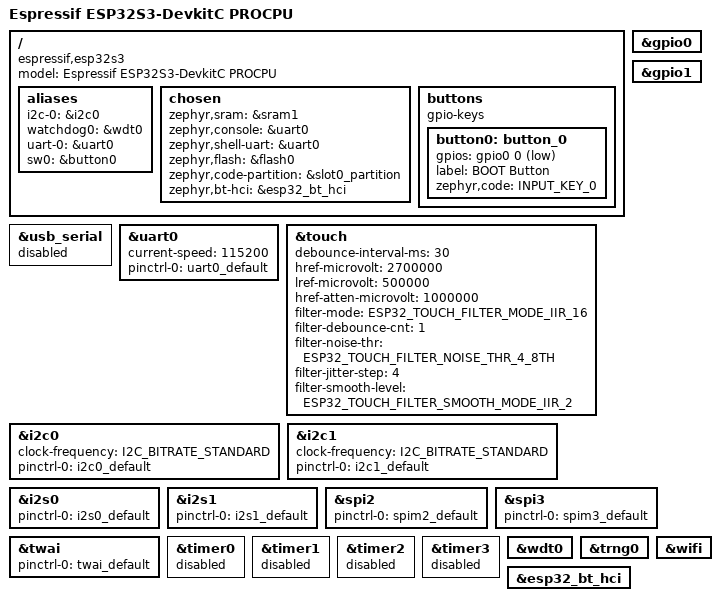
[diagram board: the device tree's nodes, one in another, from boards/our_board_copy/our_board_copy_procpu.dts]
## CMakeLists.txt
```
cmake_minimum_required(VERSION 3.20.0)

list(APPEND BOARD_ROOT ${CMAKE_CURRENT_SOURCE_DIR}/../)
find_package(Zephyr REQUIRED)
project(my_zephyr_app)

target_sources(app PRIVATE src/main.cpp)
add_subdirectory(drivers/our_driver)
```

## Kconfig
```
menuconfig LED_SUBSYSTEM
    bool "LED Subsystem"
    default n

if LED_SUBSYSTEM
    config APP_HEARTBEAT_PERIOD_MS
    	int "App Heartbeat period (100-2000)ms"
    	default 500
    	range 100 2000

    choice
        prompt "LED blink sleep time"
        default BLINK_SLEEP_1000MS

    config BLINK_SLEEP_250MS
        bool "250ms (very fast)"

    config BLINK_SLEEP_500MS
        bool "500ms (fast)"

    config BLINK_SLEEP_1000MS
        bool "1s (medium)"

    config BLINK_SLEEP_2000MS
        bool "2s (slow)"
    endchoice

    config BLINK_SLEEP_TIME_MS
        int
        depends on BLINK_SLEEP_250MS || BLINK_SLEEP_500MS || BLINK_SLEEP_1000MS || BLINK_SLEEP_2000MS
        default 250  if BLINK_SLEEP_250MS
        default 500  if BLINK_SLEEP_500MS
        default 1000 if BLINK_SLEEP_1000MS
        default 2000 if BLINK_SLEEP_2000MS
        default 0

    menuconfig ADVANCED_LED_SETTINGS
        bool "Advanced LED settings"
        default n

    if ADVANCED_LED_SETTINGS

        config LED_BRIGHTNESS
            int "LED brightness (0-100)"
            default 100
            range 0 100
            help
                Set the LED brightness level (0-100%)

        config LED_FADE_DURATION_MS
            int "LED fade duration (ms)"
            default 500
            range 0 5000
            help
                Set the duration for LED fade in/out effects in milliseconds

        menu "Expert settings"
            visible if ADVANCED_LED_SETTINGS
            config ENABLE_LED_DEBUGGING
                bool "Enable LED debugging"
                default n
                help
                    Enable debug output for LED operations (not recommended for production)

            config CUSTOM_LED_PATTERN
                bool "Custom blink pattern"
                default n
                help
                    Define a custom LED blinking pattern.
        endmenu #Expert settings

    endif #ADVANCED_LED_SETTINGS
endif #LED_SUBSYSTEM

source "Kconfig.zephyr"
rsource "drivers/our_driver/Kconfig"
```

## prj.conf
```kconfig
CONFIG_GPIO=y
CONFIG_LOG=y
CONFIG_LED_SUBSYSTEM=y
CONFIG_BLINK_SLEEP_1000MS=y
CONFIG_APP_HEARTBEAT_PERIOD_MS=1000
CONFIG_SHELL=y
CONFIG_SHELL_CMDS=y
CONFIG_SHELL_TAB=y
CONFIG_SHELL_TAB_AUTOCOMPLETION=y
CONFIG_SHELL_HISTORY=y
CONFIG_SHELL_LOG_BACKEND=y
```

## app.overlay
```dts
/{
    aliases {
        app-led = &led0;
    };

    leds {
        compatible = "gpio-leds";
        led0: led_0 {
            gpios = <&gpio0 48 GPIO_ACTIVE_HIGH>; //GPIO 48
            label = "LED 0";
        };
    };

    our_driver0: our_driver {
        compatible = "our,driver";
        status = "okay";
    };

};
```

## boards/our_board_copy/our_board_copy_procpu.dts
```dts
/*
 * Copyright (c) 2024-2025 Espressif Systems (Shanghai) Co., Ltd.
 *
 * SPDX-License-Identifier: Apache-2.0
 */
/dts-v1/;

#include <espressif/esp32s3/esp32s3_wroom_n8.dtsi>
#include <zephyr/dt-bindings/input/input-event-codes.h>
#include <zephyr/dt-bindings/input/esp32-touch-sensor-input.h>
#include <espressif/partitions_0x0_amp.dtsi>
#include "our_board_copy-pinctrl.dtsi"

/ {
	model = "Espressif ESP32S3-DevkitC PROCPU";
	compatible = "espressif,esp32s3";

	aliases {
		i2c-0 = &i2c0;
		watchdog0 = &wdt0;
		uart-0 = &uart0;
		sw0 = &button0;
	};

	chosen {
		zephyr,sram = &sram1;
		zephyr,console = &uart0;
		zephyr,shell-uart = &uart0;
		zephyr,flash = &flash0;
		zephyr,code-partition = &slot0_partition;
		zephyr,bt-hci = &esp32_bt_hci;
	};

	buttons {
		compatible = "gpio-keys";

		button0: button_0 {
			gpios = <&gpio0 0 (GPIO_PULL_UP | GPIO_ACTIVE_LOW)>;
			label = "BOOT Button";
			zephyr,code = <INPUT_KEY_0>;
		};
	};
};

&usb_serial {
	status = "disabled";
};

&uart0 {
	status = "okay";
	current-speed = <115200>;
	pinctrl-0 = <&uart0_default>;
	pinctrl-names = "default";
};

&gpio0 {
	status = "okay";
};

&gpio1 {
	status = "okay";
};

&touch {
	debounce-interval-ms = <30>;
	href-microvolt = <2700000>;
	lref-microvolt = <500000>;
	href-atten-microvolt = <1000000>;
	filter-mode = <ESP32_TOUCH_FILTER_MODE_IIR_16>;
	filter-debounce-cnt = <1>;
	filter-noise-thr = <ESP32_TOUCH_FILTER_NOISE_THR_4_8TH>;
	filter-jitter-step = <4>;
	filter-smooth-level = <ESP32_TOUCH_FILTER_SMOOTH_MODE_IIR_2>;
};

&i2c0 {
	clock-frequency = <I2C_BITRATE_STANDARD>;
	pinctrl-0 = <&i2c0_default>;
	pinctrl-names = "default";
};

&i2c1 {
	clock-frequency = <I2C_BITRATE_STANDARD>;
	pinctrl-0 = <&i2c1_default>;
	pinctrl-names = "default";
};

&i2s0 {
	pinctrl-0 = <&i2s0_default>;
	pinctrl-names = "default";
};

&i2s1 {
	pinctrl-0 = <&i2s1_default>;
	pinctrl-names = "default";
};

&spi2 {
	#address-cells = <1>;
	#size-cells = <0>;
	status = "okay";
	pinctrl-0 = <&spim2_default>;
	pinctrl-names = "default";
};

&spi3 {
	#address-cells = <1>;
	#size-cells = <0>;
	status = "okay";
	pinctrl-0 = <&spim3_default>;
	pinctrl-names = "default";
};

&twai {
	pinctrl-0 = <&twai_default>;
	pinctrl-names = "default";
};

&timer0 {
	status = "disabled";
};

&timer1 {
	status = "disabled";
};

&timer2 {
	status = "disabled";
};

&timer3 {
	status = "disabled";
};

&wdt0 {
	status = "okay";
};

&trng0 {
	status = "okay";
};

&esp32_bt_hci {
	status = "okay";
};

&wifi {
	status = "okay";
};
```

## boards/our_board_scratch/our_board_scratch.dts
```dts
/dts-v1/;

#include <espressif/esp32s3/esp32s3_wroom_n8.dtsi>

/ {
    model = "Our Board Scratch;
    compatible = "iomico,our-board-scratch";
    aliases {
        led0 = &green_led
    };

    chosen {
        zephyr,sram = &sram1;
        zephyr,flash = &flash0;
        zephyr,code-partition = &slot0_partition;
    };

    leds {
        compatible = "gpio-leds";
        green_led : led_0 {
            gpios = <&gpio0 48 GPIO_ACTIVE_LOW>;
            label = "Green Led"
        };
    };
};

&gpio0 {
    status = "okay";
};
```

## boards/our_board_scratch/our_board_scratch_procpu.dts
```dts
/dts-v1/;

#include <espressif/esp32s3/esp32s3_wroom_n8.dtsi>
#include <espressif/partitions_0x0_amp.dtsi>
#include "our_board_scratch-pinctrl.dtsi"

/ {
    model = "Our Board Scratch";
    compatible = "iomico,our-board-scratch";
    aliases {
        app-led = &led0;
    };

    chosen {
        zephyr,sram = &sram1;
        zephyr,console = &uart0;
        zephyr,shell-uart = &uart0;
        zephyr,flash = &flash0;
        zephyr,code-partition = &slot0_partition;
    };

    leds {
        compatible = "gpio-leds";
        led0: led_0 {
            gpios = <&gpio0 48 GPIO_ACTIVE_HIGH>; //GPIO 48
            label = "LED 0";
        };
    };
};

&uart0 {
    status = "okay";
    current-speed = <115200>;
    pinctrl-0 = <&uart0_default>;
    pinctrl-names = "default";
};

&gpio0 {
	status = "okay";
};
```

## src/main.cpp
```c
#include <zephyr/drivers/gpio.h>
#include <zephyr/kernel.h>
#include <zephyr/logging/log.h>
#include <zephyr/drivers/sensor.h>
#include "../drivers/our_driver/our_driver.h"

LOG_MODULE_REGISTER(main, LOG_LEVEL_INF);

int main(void)
{
    int ret = 0;
    int ret2 = 0;

    const struct device* driver = DEVICE_DT_GET(DT_NODELABEL(our_driver0));
    our_driver_set_param(driver, 42);
    struct sensor_value val;
    while (1)
    {
        ret = sensor_channel_get(driver, SENSOR_CHAN_AMBIENT_TEMP, &val);
        k_msleep(CONFIG_APP_HEARTBEAT_PERIOD_MS);
        ret2 = sensor_sample_fetch(driver);
        k_msleep(CONFIG_APP_HEARTBEAT_PERIOD_MS);
    }
    return 0;
}
```
